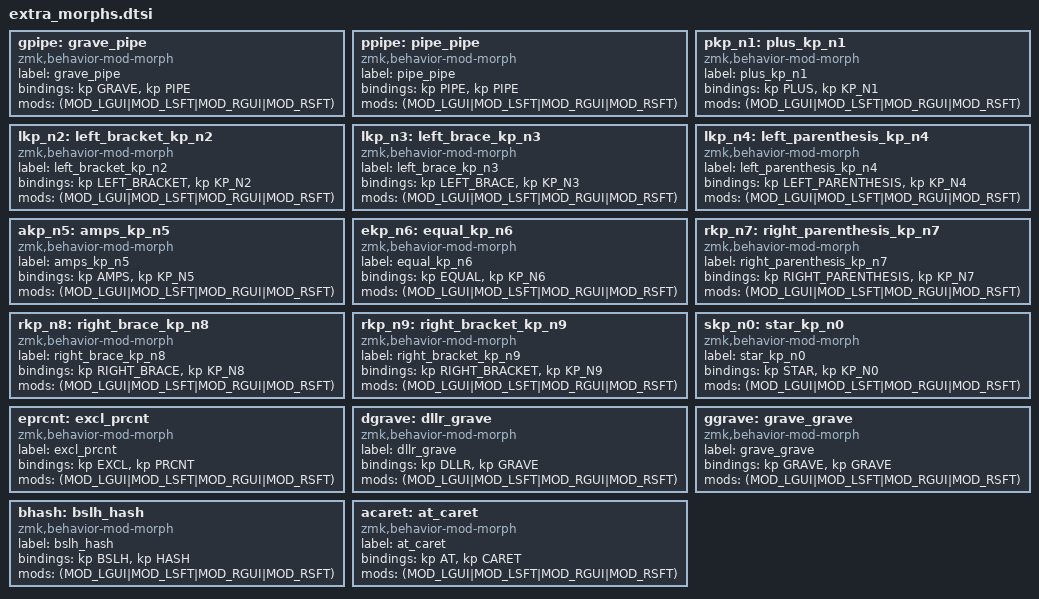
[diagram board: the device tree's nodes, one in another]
gpipe: grave_pipe {
    compatible = "zmk,behavior-mod-morph";
    label = "grave_pipe";
    #binding-cells = <0>;
    bindings = <&kp GRAVE>, <&kp PIPE>;
    mods = <(MOD_LGUI|MOD_LSFT|MOD_RGUI|MOD_RSFT)>;
};
ppipe: pipe_pipe {
    compatible = "zmk,behavior-mod-morph";
    label = "pipe_pipe";
    #binding-cells = <0>;
    bindings = <&kp PIPE>, <&kp PIPE>;
    mods = <(MOD_LGUI|MOD_LSFT|MOD_RGUI|MOD_RSFT)>;
};
pkp_n1: plus_kp_n1 {
    compatible = "zmk,behavior-mod-morph";
    label = "plus_kp_n1";
    #binding-cells = <0>;
    bindings = <&kp PLUS>, <&kp KP_N1>;
    mods = <(MOD_LGUI|MOD_LSFT|MOD_RGUI|MOD_RSFT)>;
};
lkp_n2: left_bracket_kp_n2 {
    compatible = "zmk,behavior-mod-morph";
    label = "left_bracket_kp_n2";
    #binding-cells = <0>;
    bindings = <&kp LEFT_BRACKET>, <&kp KP_N2>;
    mods = <(MOD_LGUI|MOD_LSFT|MOD_RGUI|MOD_RSFT)>;
};
lkp_n3: left_brace_kp_n3 {
    compatible = "zmk,behavior-mod-morph";
    label = "left_brace_kp_n3";
    #binding-cells = <0>;
    bindings = <&kp LEFT_BRACE>, <&kp KP_N3>;
    mods = <(MOD_LGUI|MOD_LSFT|MOD_RGUI|MOD_RSFT)>;
};
lkp_n4: left_parenthesis_kp_n4 {
    compatible = "zmk,behavior-mod-morph";
    label = "left_parenthesis_kp_n4";
    #binding-cells = <0>;
    bindings = <&kp LEFT_PARENTHESIS>, <&kp KP_N4>;
    mods = <(MOD_LGUI|MOD_LSFT|MOD_RGUI|MOD_RSFT)>;
};
akp_n5: amps_kp_n5 {
    compatible = "zmk,behavior-mod-morph";
    label = "amps_kp_n5";
    #binding-cells = <0>;
    bindings = <&kp AMPS>, <&kp KP_N5>;
    mods = <(MOD_LGUI|MOD_LSFT|MOD_RGUI|MOD_RSFT)>;
};
ekp_n6: equal_kp_n6 {
    compatible = "zmk,behavior-mod-morph";
    label = "equal_kp_n6";
    #binding-cells = <0>;
    bindings = <&kp EQUAL>, <&kp KP_N6>;
    mods = <(MOD_LGUI|MOD_LSFT|MOD_RGUI|MOD_RSFT)>;
};
rkp_n7: right_parenthesis_kp_n7 {
    compatible = "zmk,behavior-mod-morph";
    label = "right_parenthesis_kp_n7";
    #binding-cells = <0>;
    bindings = <&kp RIGHT_PARENTHESIS>, <&kp KP_N7>;
    mods = <(MOD_LGUI|MOD_LSFT|MOD_RGUI|MOD_RSFT)>;
};
rkp_n8: right_brace_kp_n8 {
    compatible = "zmk,behavior-mod-morph";
    label = "right_brace_kp_n8";
    #binding-cells = <0>;
    bindings = <&kp RIGHT_BRACE>, <&kp KP_N8>;
    mods = <(MOD_LGUI|MOD_LSFT|MOD_RGUI|MOD_RSFT)>;
};
rkp_n9: right_bracket_kp_n9 {
    compatible = "zmk,behavior-mod-morph";
    label = "right_bracket_kp_n9";
    #binding-cells = <0>;
    bindings = <&kp RIGHT_BRACKET>, <&kp KP_N9>;
    mods = <(MOD_LGUI|MOD_LSFT|MOD_RGUI|MOD_RSFT)>;
};
skp_n0: star_kp_n0 {
    compatible = "zmk,behavior-mod-morph";
    label = "star_kp_n0";
    #binding-cells = <0>;
    bindings = <&kp STAR>, <&kp KP_N0>;
    mods = <(MOD_LGUI|MOD_LSFT|MOD_RGUI|MOD_RSFT)>;
};
eprcnt: excl_prcnt {
    compatible = "zmk,behavior-mod-morph";
    label = "excl_prcnt";
    #binding-cells = <0>;
    bindings = <&kp EXCL>, <&kp PRCNT>;
    mods = <(MOD_LGUI|MOD_LSFT|MOD_RGUI|MOD_RSFT)>;
};

dgrave: dllr_grave {
    compatible = "zmk,behavior-mod-morph";
    label = "dllr_grave";
    #binding-cells = <0>;
    bindings = <&kp DLLR>, <&kp GRAVE>;
    mods = <(MOD_LGUI|MOD_LSFT|MOD_RGUI|MOD_RSFT)>;
};
ggrave: grave_grave {
    compatible = "zmk,behavior-mod-morph";
    label = "grave_grave";
    #binding-cells = <0>;
    bindings = <&kp GRAVE>, <&kp GRAVE>;
    mods = <(MOD_LGUI|MOD_LSFT|MOD_RGUI|MOD_RSFT)>;
};
bhash: bslh_hash {
    compatible = "zmk,behavior-mod-morph";
    label = "bslh_hash";
    #binding-cells = <0>;
    bindings = <&kp BSLH>, <&kp HASH>;
    mods = <(MOD_LGUI|MOD_LSFT|MOD_RGUI|MOD_RSFT)>;
};
acaret: at_caret {
    compatible = "zmk,behavior-mod-morph";
    label = "at_caret";
    #binding-cells = <0>;
    bindings = <&kp AT>, <&kp CARET>;
    mods = <(MOD_LGUI|MOD_LSFT|MOD_RGUI|MOD_RSFT)>;
};
